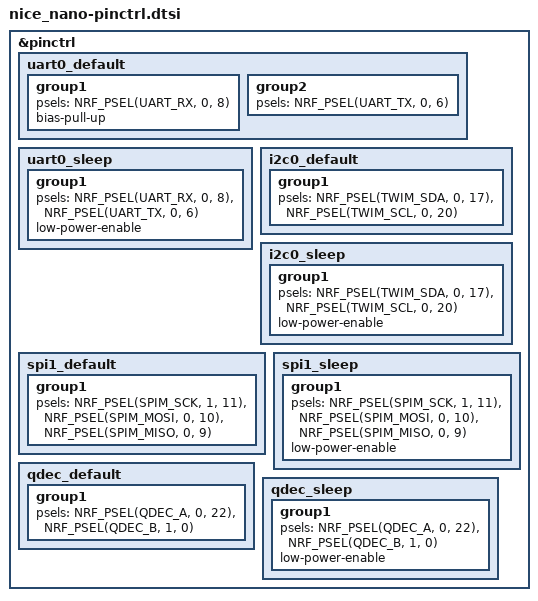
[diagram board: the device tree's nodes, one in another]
/*
 * Copyright (c) 2022 The ZMK Contributors
 * SPDX-License-Identifier: MIT
 */

&pinctrl {
    uart0_default: uart0_default {
        group1 {
            psels = <NRF_PSEL(UART_RX, 0, 8)>;
            bias-pull-up;
        };
        group2 {
            psels = <NRF_PSEL(UART_TX, 0, 6)>;
        };
    };

    uart0_sleep: uart0_sleep {
        group1 {
            psels = <NRF_PSEL(UART_RX, 0, 8)>,
                <NRF_PSEL(UART_TX, 0, 6)>;
            low-power-enable;
        };
    };

    i2c0_default: i2c0_default {
        group1 {
            psels = <NRF_PSEL(TWIM_SDA, 0, 17)>,
                <NRF_PSEL(TWIM_SCL, 0, 20)>;
        };
    };

    i2c0_sleep: i2c0_sleep {
        group1 {
            psels = <NRF_PSEL(TWIM_SDA, 0, 17)>,
                <NRF_PSEL(TWIM_SCL, 0, 20)>;
            low-power-enable;
        };
    };

    spi1_default: spi1_default {
        group1 {
            psels = <NRF_PSEL(SPIM_SCK, 1, 11)>,   /* D14 - SCLK */
                <NRF_PSEL(SPIM_MOSI, 0, 10)>,  /* D16 - MOSI */
                <NRF_PSEL(SPIM_MISO, 0, 9)>;   /* D10 - MISO */
        };
    };

    spi1_sleep: spi1_sleep {
        group1 {
            psels = <NRF_PSEL(SPIM_SCK, 1, 11)>,   /* D14 - SCLK */
                <NRF_PSEL(SPIM_MOSI, 0, 10)>,  /* D16 - MOSI */
                <NRF_PSEL(SPIM_MISO, 0, 9)>;   /* D10 - MISO */
            low-power-enable;
        };
    };

    qdec_default: qdec_default {
        group1 {
            psels = <NRF_PSEL(QDEC_A, 0, 22)>,   /* D5 - Encoder A */
                <NRF_PSEL(QDEC_B, 1, 0)>;    /* D6 - Encoder B */
        };
    };

    qdec_sleep: qdec_sleep {
        group1 {
            psels = <NRF_PSEL(QDEC_A, 0, 22)>,
                <NRF_PSEL(QDEC_B, 1, 0)>;
            low-power-enable;
        };
    };
};
